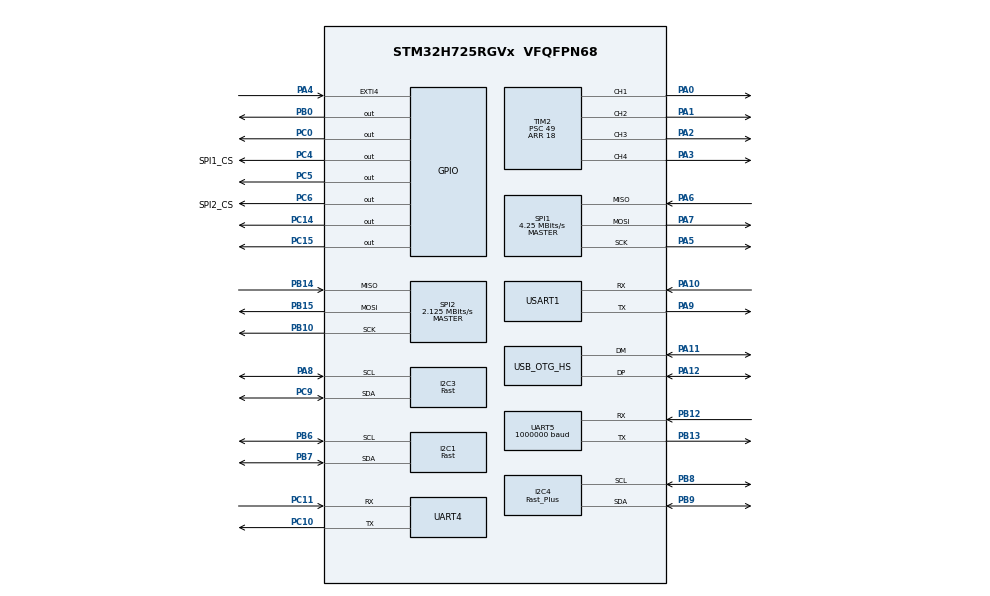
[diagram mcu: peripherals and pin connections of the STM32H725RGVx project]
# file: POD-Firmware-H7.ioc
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Bdma.I2C4_RX.0.Direction=DMA_PERIPH_TO_MEMORY
Bdma.I2C4_RX.0.EventEnable=DISABLE
Bdma.I2C4_RX.0.Instance=BDMA_Channel0
Bdma.I2C4_RX.0.MemDataAlignment=DMA_MDATAALIGN_BYTE
Bdma.I2C4_RX.0.MemInc=DMA_MINC_ENABLE
Bdma.I2C4_RX.0.Mode=DMA_NORMAL
Bdma.I2C4_RX.0.PeriphDataAlignment=DMA_PDATAALIGN_BYTE
Bdma.I2C4_RX.0.PeriphInc=DMA_PINC_DISABLE
Bdma.I2C4_RX.0.Polarity=HAL_DMAMUX_REQ_GEN_RISING
Bdma.I2C4_RX.0.Priority=DMA_PRIORITY_MEDIUM
Bdma.I2C4_RX.0.RequestNumber=1
Bdma.I2C4_RX.0.SignalID=NONE
Bdma.I2C4_RX.0.SyncEnable=DISABLE
Bdma.I2C4_RX.0.SyncPolarity=HAL_DMAMUX_SYNC_NO_EVENT
Bdma.I2C4_RX.0.SyncRequestNumber=1
Bdma.I2C4_RX.0.SyncSignalID=NONE
Bdma.Request0=I2C4_RX
Bdma.RequestsNb=1
CORTEX_M7.Enable_Spec=__NULL
Dma.I2C1_RX.0.Direction=DMA_PERIPH_TO_MEMORY
Dma.I2C1_RX.0.EventEnable=DISABLE
Dma.I2C1_RX.0.FIFOMode=DMA_FIFOMODE_DISABLE
Dma.I2C1_RX.0.Instance=DMA1_Stream0
Dma.I2C1_RX.0.MemDataAlignment=DMA_MDATAALIGN_BYTE
Dma.I2C1_RX.0.MemInc=DMA_MINC_ENABLE
Dma.I2C1_RX.0.Mode=DMA_NORMAL
Dma.I2C1_RX.0.PeriphDataAlignment=DMA_PDATAALIGN_BYTE
Dma.I2C1_RX.0.PeriphInc=DMA_PINC_DISABLE
Dma.I2C1_RX.0.Polarity=HAL_DMAMUX_REQ_GEN_RISING
Dma.I2C1_RX.0.Priority=DMA_PRIORITY_LOW
Dma.I2C1_RX.0.RequestNumber=1
Dma.I2C1_RX.0.SignalID=NONE
Dma.I2C1_RX.0.SyncEnable=DISABLE
Dma.I2C1_RX.0.SyncPolarity=HAL_DMAMUX_SYNC_NO_EVENT
Dma.I2C1_RX.0.SyncRequestNumber=1
Dma.I2C1_RX.0.SyncSignalID=NONE
Dma.I2C3_RX.1.Direction=DMA_PERIPH_TO_MEMORY
Dma.I2C3_RX.1.EventEnable=DISABLE
Dma.I2C3_RX.1.FIFOMode=DMA_FIFOMODE_DISABLE
Dma.I2C3_RX.1.Instance=DMA1_Stream1
Dma.I2C3_RX.1.MemDataAlignment=DMA_MDATAALIGN_BYTE
Dma.I2C3_RX.1.MemInc=DMA_MINC_ENABLE
Dma.I2C3_RX.1.Mode=DMA_NORMAL
Dma.I2C3_RX.1.PeriphDataAlignment=DMA_PDATAALIGN_BYTE
Dma.I2C3_RX.1.PeriphInc=DMA_PINC_DISABLE
Dma.I2C3_RX.1.Polarity=HAL_DMAMUX_REQ_GEN_RISING
Dma.I2C3_RX.1.Priority=DMA_PRIORITY_HIGH
Dma.I2C3_RX.1.RequestNumber=1
Dma.I2C3_RX.1.SignalID=NONE
Dma.I2C3_RX.1.SyncEnable=DISABLE
Dma.I2C3_RX.1.SyncPolarity=HAL_DMAMUX_SYNC_NO_EVENT
Dma.I2C3_RX.1.SyncRequestNumber=1
Dma.I2C3_RX.1.SyncSignalID=NONE
Dma.Request0=I2C1_RX
Dma.Request1=I2C3_RX
Dma.Request10=SPI2_TX
Dma.Request11=UART4_TX
Dma.Request12=UART4_RX
Dma.Request13=UART5_RX
Dma.Request2=SPI1_RX
Dma.Request3=UART5_TX
Dma.Request4=TIM2_CH1
Dma.Request5=TIM2_CH3
Dma.Request6=TIM2_CH4
Dma.Request7=TIM2_CH2
Dma.Request8=SPI2_RX
Dma.Request9=SPI1_TX
Dma.SPI1_RX.2.Direction=DMA_PERIPH_TO_MEMORY
Dma.SPI1_RX.2.EventEnable=DISABLE
Dma.SPI1_RX.2.FIFOMode=DMA_FIFOMODE_DISABLE
Dma.SPI1_RX.2.Instance=DMA1_Stream2
Dma.SPI1_RX.2.MemDataAlignment=DMA_MDATAALIGN_BYTE
Dma.SPI1_RX.2.MemInc=DMA_MINC_ENABLE
Dma.SPI1_RX.2.Mode=DMA_NORMAL
Dma.SPI1_RX.2.PeriphDataAlignment=DMA_PDATAALIGN_BYTE
Dma.SPI1_RX.2.PeriphInc=DMA_PINC_DISABLE
Dma.SPI1_RX.2.Polarity=HAL_DMAMUX_REQ_GEN_RISING
Dma.SPI1_RX.2.Priority=DMA_PRIORITY_HIGH
Dma.SPI1_RX.2.RequestNumber=1
Dma.SPI1_RX.2.SignalID=NONE
Dma.SPI1_RX.2.SyncEnable=DISABLE
Dma.SPI1_RX.2.SyncPolarity=HAL_DMAMUX_SYNC_NO_EVENT
Dma.SPI1_RX.2.SyncRequestNumber=1
Dma.SPI1_RX.2.SyncSignalID=NONE
Dma.SPI1_TX.9.Direction=DMA_MEMORY_TO_PERIPH
Dma.SPI1_TX.9.EventEnable=DISABLE
Dma.SPI1_TX.9.FIFOMode=DMA_FIFOMODE_DISABLE
Dma.SPI1_TX.9.Instance=DMA2_Stream1
Dma.SPI1_TX.9.MemDataAlignment=DMA_MDATAALIGN_BYTE
Dma.SPI1_TX.9.MemInc=DMA_MINC_ENABLE
Dma.SPI1_TX.9.Mode=DMA_NORMAL
Dma.SPI1_TX.9.PeriphDataAlignment=DMA_PDATAALIGN_BYTE
Dma.SPI1_TX.9.PeriphInc=DMA_PINC_DISABLE
Dma.SPI1_TX.9.Polarity=HAL_DMAMUX_REQ_GEN_RISING
Dma.SPI1_TX.9.Priority=DMA_PRIORITY_HIGH
Dma.SPI1_TX.9.RequestNumber=1
Dma.SPI1_TX.9.SignalID=NONE
Dma.SPI1_TX.9.SyncEnable=DISABLE
Dma.SPI1_TX.9.SyncPolarity=HAL_DMAMUX_SYNC_NO_EVENT
Dma.SPI1_TX.9.SyncRequestNumber=1
Dma.SPI1_TX.9.SyncSignalID=NONE
Dma.SPI2_RX.8.Direction=DMA_PERIPH_TO_MEMORY
Dma.SPI2_RX.8.EventEnable=DISABLE
Dma.SPI2_RX.8.FIFOMode=DMA_FIFOMODE_DISABLE
Dma.SPI2_RX.8.Instance=DMA1_Stream3
Dma.SPI2_RX.8.MemDataAlignment=DMA_MDATAALIGN_BYTE
Dma.SPI2_RX.8.MemInc=DMA_MINC_ENABLE
Dma.SPI2_RX.8.Mode=DMA_NORMAL
Dma.SPI2_RX.8.PeriphDataAlignment=DMA_PDATAALIGN_BYTE
Dma.SPI2_RX.8.PeriphInc=DMA_PINC_DISABLE
Dma.SPI2_RX.8.Polarity=HAL_DMAMUX_REQ_GEN_RISING
Dma.SPI2_RX.8.Priority=DMA_PRIORITY_HIGH
Dma.SPI2_RX.8.RequestNumber=1
Dma.SPI2_RX.8.SignalID=NONE
Dma.SPI2_RX.8.SyncEnable=DISABLE
Dma.SPI2_RX.8.SyncPolarity=HAL_DMAMUX_SYNC_NO_EVENT
Dma.SPI2_RX.8.SyncRequestNumber=1
Dma.SPI2_RX.8.SyncSignalID=NONE
Dma.SPI2_TX.10.Direction=DMA_MEMORY_TO_PERIPH
Dma.SPI2_TX.10.EventEnable=DISABLE
Dma.SPI2_TX.10.FIFOMode=DMA_FIFOMODE_DISABLE
Dma.SPI2_TX.10.Instance=DMA2_Stream2
Dma.SPI2_TX.10.MemDataAlignment=DMA_MDATAALIGN_BYTE
Dma.SPI2_TX.10.MemInc=DMA_MINC_ENABLE
Dma.SPI2_TX.10.Mode=DMA_NORMAL
Dma.SPI2_TX.10.PeriphDataAlignment=DMA_PDATAALIGN_BYTE
Dma.SPI2_TX.10.PeriphInc=DMA_PINC_DISABLE
Dma.SPI2_TX.10.Polarity=HAL_DMAMUX_REQ_GEN_RISING
Dma.SPI2_TX.10.Priority=DMA_PRIORITY_HIGH
Dma.SPI2_TX.10.RequestNumber=1
Dma.SPI2_TX.10.SignalID=NONE
Dma.SPI2_TX.10.SyncEnable=DISABLE
Dma.SPI2_TX.10.SyncPolarity=HAL_DMAMUX_SYNC_NO_EVENT
Dma.SPI2_TX.10.SyncRequestNumber=1
Dma.SPI2_TX.10.SyncSignalID=NONE
Dma.TIM2_CH1.4.Direction=DMA_MEMORY_TO_PERIPH
Dma.TIM2_CH1.4.EventEnable=DISABLE
Dma.TIM2_CH1.4.FIFOMode=DMA_FIFOMODE_DISABLE
Dma.TIM2_CH1.4.Instance=DMA1_Stream4
Dma.TIM2_CH1.4.MemDataAlignment=DMA_MDATAALIGN_WORD
Dma.TIM2_CH1.4.MemInc=DMA_MINC_ENABLE
Dma.TIM2_CH1.4.Mode=DMA_NORMAL
Dma.TIM2_CH1.4.PeriphDataAlignment=DMA_PDATAALIGN_WORD
Dma.TIM2_CH1.4.PeriphInc=DMA_PINC_DISABLE
Dma.TIM2_CH1.4.Polarity=HAL_DMAMUX_REQ_GEN_RISING
Dma.TIM2_CH1.4.Priority=DMA_PRIORITY_VERY_HIGH
Dma.TIM2_CH1.4.RequestNumber=1
Dma.TIM2_CH1.4.SignalID=NONE
Dma.TIM2_CH1.4.SyncEnable=DISABLE
Dma.TIM2_CH1.4.SyncPolarity=HAL_DMAMUX_SYNC_NO_EVENT
Dma.TIM2_CH1.4.SyncRequestNumber=1
Dma.TIM2_CH1.4.SyncSignalID=NONE
Dma.TIM2_CH2.7.Direction=DMA_MEMORY_TO_PERIPH
Dma.TIM2_CH2.7.EventEnable=DISABLE
Dma.TIM2_CH2.7.FIFOMode=DMA_FIFOMODE_DISABLE
Dma.TIM2_CH2.7.Instance=DMA1_Stream5
Dma.TIM2_CH2.7.MemDataAlignment=DMA_MDATAALIGN_WORD
Dma.TIM2_CH2.7.MemInc=DMA_MINC_ENABLE
Dma.TIM2_CH2.7.Mode=DMA_NORMAL
Dma.TIM2_CH2.7.PeriphDataAlignment=DMA_PDATAALIGN_WORD
Dma.TIM2_CH2.7.PeriphInc=DMA_PINC_DISABLE
Dma.TIM2_CH2.7.Polarity=HAL_DMAMUX_REQ_GEN_RISING
Dma.TIM2_CH2.7.Priority=DMA_PRIORITY_VERY_HIGH
Dma.TIM2_CH2.7.RequestNumber=1
Dma.TIM2_CH2.7.SignalID=NONE
Dma.TIM2_CH2.7.SyncEnable=DISABLE
Dma.TIM2_CH2.7.SyncPolarity=HAL_DMAMUX_SYNC_NO_EVENT
Dma.TIM2_CH2.7.SyncRequestNumber=1
Dma.TIM2_CH2.7.SyncSignalID=NONE
Dma.TIM2_CH3.5.Direction=DMA_MEMORY_TO_PERIPH
Dma.TIM2_CH3.5.EventEnable=DISABLE
Dma.TIM2_CH3.5.FIFOMode=DMA_FIFOMODE_DISABLE
Dma.TIM2_CH3.5.Instance=DMA1_Stream6
Dma.TIM2_CH3.5.MemDataAlignment=DMA_MDATAALIGN_WORD
Dma.TIM2_CH3.5.MemInc=DMA_MINC_ENABLE
Dma.TIM2_CH3.5.Mode=DMA_NORMAL
Dma.TIM2_CH3.5.PeriphDataAlignment=DMA_PDATAALIGN_WORD
Dma.TIM2_CH3.5.PeriphInc=DMA_PINC_DISABLE
Dma.TIM2_CH3.5.Polarity=HAL_DMAMUX_REQ_GEN_RISING
Dma.TIM2_CH3.5.Priority=DMA_PRIORITY_VERY_HIGH
Dma.TIM2_CH3.5.RequestNumber=1
Dma.TIM2_CH3.5.SignalID=NONE
Dma.TIM2_CH3.5.SyncEnable=DISABLE
Dma.TIM2_CH3.5.SyncPolarity=HAL_DMAMUX_SYNC_NO_EVENT
Dma.TIM2_CH3.5.SyncRequestNumber=1
Dma.TIM2_CH3.5.SyncSignalID=NONE
Dma.TIM2_CH4.6.Direction=DMA_MEMORY_TO_PERIPH
Dma.TIM2_CH4.6.EventEnable=DISABLE
Dma.TIM2_CH4.6.FIFOMode=DMA_FIFOMODE_DISABLE
Dma.TIM2_CH4.6.Instance=DMA1_Stream7
Dma.TIM2_CH4.6.MemDataAlignment=DMA_MDATAALIGN_WORD
Dma.TIM2_CH4.6.MemInc=DMA_MINC_ENABLE
Dma.TIM2_CH4.6.Mode=DMA_NORMAL
Dma.TIM2_CH4.6.PeriphDataAlignment=DMA_PDATAALIGN_WORD
Dma.TIM2_CH4.6.PeriphInc=DMA_PINC_DISABLE
Dma.TIM2_CH4.6.Polarity=HAL_DMAMUX_REQ_GEN_RISING
Dma.TIM2_CH4.6.Priority=DMA_PRIORITY_VERY_HIGH
Dma.TIM2_CH4.6.RequestNumber=1
Dma.TIM2_CH4.6.SignalID=NONE
Dma.TIM2_CH4.6.SyncEnable=DISABLE
Dma.TIM2_CH4.6.SyncPolarity=HAL_DMAMUX_SYNC_NO_EVENT
Dma.TIM2_CH4.6.SyncRequestNumber=1
Dma.TIM2_CH4.6.SyncSignalID=NONE
Dma.UART4_RX.12.Direction=DMA_PERIPH_TO_MEMORY
Dma.UART4_RX.12.EventEnable=DISABLE
Dma.UART4_RX.12.FIFOMode=DMA_FIFOMODE_DISABLE
Dma.UART4_RX.12.Instance=DMA2_Stream4
Dma.UART4_RX.12.MemDataAlignment=DMA_MDATAALIGN_BYTE
Dma.UART4_RX.12.MemInc=DMA_MINC_ENABLE
Dma.UART4_RX.12.Mode=DMA_NORMAL
Dma.UART4_RX.12.PeriphDataAlignment=DMA_PDATAALIGN_BYTE
Dma.UART4_RX.12.PeriphInc=DMA_PINC_DISABLE
Dma.UART4_RX.12.Polarity=HAL_DMAMUX_REQ_GEN_RISING
Dma.UART4_RX.12.Priority=DMA_PRIORITY_MEDIUM
Dma.UART4_RX.12.RequestNumber=1
Dma.UART4_RX.12.SignalID=NONE
Dma.UART4_RX.12.SyncEnable=DISABLE
Dma.UART4_RX.12.SyncPolarity=HAL_DMAMUX_SYNC_NO_EVENT
Dma.UART4_RX.12.SyncRequestNumber=1
Dma.UART4_RX.12.SyncSignalID=NONE
Dma.UART4_TX.11.Direction=DMA_MEMORY_TO_PERIPH
Dma.UART4_TX.11.EventEnable=DISABLE
Dma.UART4_TX.11.FIFOMode=DMA_FIFOMODE_DISABLE
Dma.UART4_TX.11.Instance=DMA2_Stream3
Dma.UART4_TX.11.MemDataAlignment=DMA_MDATAALIGN_BYTE
Dma.UART4_TX.11.MemInc=DMA_MINC_ENABLE
Dma.UART4_TX.11.Mode=DMA_NORMAL
Dma.UART4_TX.11.PeriphDataAlignment=DMA_PDATAALIGN_BYTE
Dma.UART4_TX.11.PeriphInc=DMA_PINC_DISABLE
Dma.UART4_TX.11.Polarity=HAL_DMAMUX_REQ_GEN_RISING
Dma.UART4_TX.11.Priority=DMA_PRIORITY_MEDIUM
Dma.UART4_TX.11.RequestNumber=1
Dma.UART4_TX.11.SignalID=NONE
Dma.UART4_TX.11.SyncEnable=DISABLE
Dma.UART4_TX.11.SyncPolarity=HAL_DMAMUX_SYNC_NO_EVENT
Dma.UART4_TX.11.SyncRequestNumber=1
Dma.UART4_TX.11.SyncSignalID=NONE
Dma.UART5_RX.13.Direction=DMA_PERIPH_TO_MEMORY
Dma.UART5_RX.13.EventEnable=DISABLE
Dma.UART5_RX.13.FIFOMode=DMA_FIFOMODE_DISABLE
Dma.UART5_RX.13.Instance=DMA2_Stream5
Dma.UART5_RX.13.MemDataAlignment=DMA_MDATAALIGN_BYTE
Dma.UART5_RX.13.MemInc=DMA_MINC_ENABLE
Dma.UART5_RX.13.Mode=DMA_CIRCULAR
Dma.UART5_RX.13.PeriphDataAlignment=DMA_PDATAALIGN_BYTE
Dma.UART5_RX.13.PeriphInc=DMA_PINC_DISABLE
Dma.UART5_RX.13.Polarity=HAL_DMAMUX_REQ_GEN_RISING
Dma.UART5_RX.13.Priority=DMA_PRIORITY_VERY_HIGH
Dma.UART5_RX.13.RequestNumber=1
Dma.UART5_RX.13.SignalID=NONE
Dma.UART5_RX.13.SyncEnable=DISABLE
Dma.UART5_RX.13.SyncPolarity=HAL_DMAMUX_SYNC_NO_EVENT
Dma.UART5_RX.13.SyncRequestNumber=1
Dma.UART5_RX.13.SyncSignalID=NONE
Dma.UART5_TX.3.Direction=DMA_MEMORY_TO_PERIPH
Dma.UART5_TX.3.EventEnable=DISABLE
Dma.UART5_TX.3.FIFOMode=DMA_FIFOMODE_DISABLE
Dma.UART5_TX.3.Instance=DMA2_Stream0
Dma.UART5_TX.3.MemDataAlignment=DMA_MDATAALIGN_BYTE
Dma.UART5_TX.3.MemInc=DMA_MINC_ENABLE
Dma.UART5_TX.3.Mode=DMA_NORMAL
Dma.UART5_TX.3.PeriphDataAlignment=DMA_PDATAALIGN_BYTE
Dma.UART5_TX.3.PeriphInc=DMA_PINC_DISABLE
Dma.UART5_TX.3.Polarity=HAL_DMAMUX_REQ_GEN_RISING
Dma.UART5_TX.3.Priority=DMA_PRIORITY_MEDIUM
Dma.UART5_TX.3.RequestNumber=1
Dma.UART5_TX.3.SignalID=NONE
Dma.UART5_TX.3.SyncEnable=DISABLE
Dma.UART5_TX.3.SyncPolarity=HAL_DMAMUX_SYNC_NO_EVENT
Dma.UART5_TX.3.SyncRequestNumber=1
Dma.UART5_TX.3.SyncSignalID=NONE
FREERTOS.Tasks01=defaultTask,24,128,StartDefaultTask,Default,NULL,Dynamic,NULL,NULL
FREERTOS.configENABLE_FPU=1
I2C1.I2C_Speed_Mode=I2C_Fast
I2C1.Timing=0x00D049F7
I2C3.I2C_Speed_Mode=I2C_Fast
I2C3.Timing=0x00D049F7
I2C4.I2C_Speed_Mode=I2C_Fast_Plus
I2C4.Timing=0x00601B59
Mcu.Family=STM32H7
Mcu.Name=STM32H725RGVx
Mcu.Package=VFQFPN68
NVIC.BDMA_Channel0_IRQn=true\:6\:0\:true\:false\:true\:true\:false\:true\:true
NVIC.DMA1_Stream0_IRQn=true\:6\:0\:true\:false\:true\:true\:false\:true\:true
NVIC.DMA1_Stream1_IRQn=true\:6\:0\:true\:false\:true\:true\:false\:true\:true
NVIC.DMA1_Stream2_IRQn=true\:7\:0\:true\:false\:true\:true\:false\:true\:true
NVIC.DMA1_Stream3_IRQn=true\:6\:0\:true\:false\:true\:true\:false\:true\:true
NVIC.DMA1_Stream4_IRQn=true\:6\:0\:true\:false\:true\:true\:false\:true\:true
NVIC.DMA1_Stream5_IRQn=true\:6\:0\:true\:false\:true\:true\:false\:true\:true
NVIC.DMA1_Stream6_IRQn=true\:6\:0\:true\:false\:true\:true\:false\:true\:true
NVIC.DMA1_Stream7_IRQn=true\:6\:0\:true\:false\:true\:true\:false\:true\:true
NVIC.DMA2_Stream0_IRQn=true\:6\:0\:true\:false\:true\:true\:false\:true\:true
NVIC.DMA2_Stream1_IRQn=true\:7\:0\:true\:false\:true\:true\:false\:true\:true
NVIC.DMA2_Stream2_IRQn=true\:6\:0\:true\:false\:true\:true\:false\:true\:true
NVIC.DMA2_Stream3_IRQn=true\:6\:0\:true\:false\:true\:true\:false\:true\:true
NVIC.DMA2_Stream4_IRQn=true\:6\:0\:true\:false\:true\:true\:false\:true\:true
NVIC.DMA2_Stream5_IRQn=true\:5\:0\:false\:false\:true\:true\:false\:true\:true
NVIC.I2C1_EV_IRQn=true\:6\:0\:true\:false\:true\:true\:true\:true\:true
NVIC.I2C3_EV_IRQn=true\:6\:0\:true\:false\:true\:true\:true\:true\:true
NVIC.I2C4_EV_IRQn=true\:7\:0\:true\:false\:true\:true\:true\:true\:true
NVIC.OTG_HS_IRQn=true\:6\:0\:true\:false\:true\:true\:false\:true\:true
NVIC.PriorityGroup=NVIC_PRIORITYGROUP_4
NVIC.SPI1_IRQn=true\:6\:0\:true\:false\:true\:true\:true\:true\:true
NVIC.SPI2_IRQn=true\:6\:0\:true\:false\:true\:true\:true\:true\:true
NVIC.TIM1_UP_IRQn=true\:15\:0\:false\:false\:true\:false\:false\:true\:true
NVIC.TIM6_DAC_IRQn=true\:6\:0\:true\:false\:true\:true\:true\:true\:true
NVIC.TimeBase=TIM1_UP_IRQn
NVIC.TimeBaseIP=TIM1
NVIC.UART4_IRQn=true\:6\:0\:true\:false\:true\:true\:true\:true\:true
NVIC.UART5_IRQn=true\:6\:0\:true\:false\:true\:true\:true\:true\:true
PA0.Signal=S_TIM2_CH1_ETR
PA1.Signal=S_TIM2_CH2
PA10.Mode=Asynchronous
PA10.Signal=USART1_RX
PA11.Mode=Device_Only_FS
PA11.Signal=USB_OTG_HS_DM
PA12.Mode=Device_Only_FS
PA12.Signal=USB_OTG_HS_DP
PA13(JTMS/SWDIO).Signal=DEBUG_JTMS-SWDIO
PA14(JTCK/SWCLK).Signal=DEBUG_JTCK-SWCLK
PA2.Signal=S_TIM2_CH3
PA3.Signal=S_TIM2_CH4
PA4.Signal=GPXTI4
PA5.Mode=Full_Duplex_Master
PA5.Signal=SPI1_SCK
PA6.Mode=Full_Duplex_Master
PA6.Signal=SPI1_MISO
PA7.Mode=Full_Duplex_Master
PA7.Signal=SPI1_MOSI
PA8.Mode=I2C
PA8.Signal=I2C3_SCL
PA9.Mode=Asynchronous
PA9.Signal=USART1_TX
PB0.Signal=GPIO_Output
PB10.Mode=Full_Duplex_Master
PB10.Signal=SPI2_SCK
PB12.Mode=Asynchronous
PB12.Signal=UART5_RX
PB13.Mode=Asynchronous
PB13.Signal=UART5_TX
PB14.Mode=Full_Duplex_Master
PB14.Signal=SPI2_MISO
PB15.Mode=Full_Duplex_Master
PB15.Signal=SPI2_MOSI
PB3(JTDO/TRACESWO).Signal=DEBUG_JTDO-SWO
PB6.Mode=I2C
PB6.Signal=I2C1_SCL
PB7.Mode=I2C
PB7.Signal=I2C1_SDA
PB8.Mode=I2C
PB8.Signal=I2C4_SCL
PB9.Mode=I2C
PB9.Signal=I2C4_SDA
PC0.Signal=GPIO_Output
PC10.Mode=Asynchronous
PC10.Signal=UART4_TX
PC11.Mode=Asynchronous
PC11.Signal=UART4_RX
PC14-OSC32_IN.Signal=GPIO_Output
PC15-OSC32_OUT.Signal=GPIO_Output
PC4.GPIO_Label=SPI1_CS
PC4.Signal=GPIO_Output
PC5.Signal=GPIO_Output
PC6.GPIO_Label=SPI2_CS
PC6.Signal=GPIO_Output
PC9.Mode=I2C
PC9.Signal=I2C3_SDA
PH0-OSC_IN.Mode=HSE-External-Oscillator
PH0-OSC_IN.Signal=RCC_OSC_IN
PH1-OSC_OUT.Mode=HSE-External-Oscillator
PH1-OSC_OUT.Signal=RCC_OSC_OUT
ProjectManager.HeapSize=0x200
ProjectManager.StackSize=0x400
ProjectManager.TargetToolchain=Makefile
RCC.ADCFreq_Value=16125000
RCC.APB1Freq_Value=136000000
RCC.APB2Freq_Value=136000000
RCC.APB3Freq_Value=136000000
RCC.APB4Freq_Value=136000000
RCC.CortexFreq_Value=544000000
RCC.D1PPRE=RCC_APB3_DIV2
RCC.D2PPRE1=RCC_APB1_DIV2
RCC.D2PPRE2=RCC_APB2_DIV2
RCC.D3PPRE=RCC_APB4_DIV2
RCC.DIVM1=1
RCC.DIVM3=1
RCC.DIVN1=68
RCC.DIVN3=24
RCC.DIVP1=1
RCC.DIVQ1=4
RCC.DIVQ3=4
RCC.DIVR3=4
RCC.HCLKFreq_Value=272000000
RCC.HPRE=RCC_HCLK_DIV2
RCC.HSE_VALUE=8000000
RCC.PLL2FRACN=0
RCC.PLL3FRACN=0
RCC.PLLFRACN=0
RCC.PLLSourceVirtual=RCC_PLLSOURCE_HSE
RCC.SYSCLKFreq_VALUE=544000000
RCC.SYSCLKSource=RCC_SYSCLKSOURCE_PLLCLK
RCC.USBCLockSelection=RCC_USBCLKSOURCE_PLL3
RCC.USBFreq_Value=48000000
SH.S_TIM2_CH1_ETR.0=TIM2_CH1,PWM Generation1 CH1
SH.S_TIM2_CH2.0=TIM2_CH2,PWM Generation2 CH2
SH.S_TIM2_CH3.0=TIM2_CH3,PWM Generation3 CH3
SH.S_TIM2_CH4.0=TIM2_CH4,PWM Generation4 CH4
SPI1.BaudRatePrescaler=SPI_BAUDRATEPRESCALER_32
SPI1.CalculateBaudRate=4.25 MBits/s
SPI1.DataSize=SPI_DATASIZE_8BIT
SPI1.Direction=SPI_DIRECTION_2LINES
SPI1.Mode=SPI_MODE_MASTER
SPI1.VirtualType=VM_MASTER
SPI2.BaudRatePrescaler=SPI_BAUDRATEPRESCALER_64
SPI2.CalculateBaudRate=2.125 MBits/s
SPI2.DataSize=SPI_DATASIZE_8BIT
SPI2.Direction=SPI_DIRECTION_2LINES
SPI2.Mode=SPI_MODE_MASTER
SPI2.VirtualType=VM_MASTER
TIM2.AutoReloadPreload=TIM_AUTORELOAD_PRELOAD_ENABLE
TIM2.Channel-PWM\ Generation1\ CH1=TIM_CHANNEL_1
TIM2.Channel-PWM\ Generation2\ CH2=TIM_CHANNEL_2
TIM2.Channel-PWM\ Generation3\ CH3=TIM_CHANNEL_3
TIM2.Channel-PWM\ Generation4\ CH4=TIM_CHANNEL_4
TIM2.Period=18
TIM2.Prescaler=49
TIM6.AutoReloadPreload=TIM_AUTORELOAD_PRELOAD_ENABLE
TIM6.Period=499
TIM6.Prescaler=271
TIM6.TIM_MasterOutputTrigger=TIM_TRGO_UPDATE
TIM7.AutoReloadPreload=TIM_AUTORELOAD_PRELOAD_ENABLE
TIM7.Prescaler=271
UART5.BaudRate=1000000
USART1.VirtualMode-Asynchronous=VM_ASYNC
USB_DEVICE.CLASS_NAME_HS=CDC
USB_DEVICE.VirtualMode=Cdc
USB_DEVICE.VirtualModeHS=Cdc_HS
USB_OTG_HS.VirtualMode=Device_Only_FS
VP_FREERTOS_VS_CMSIS_V2.Mode=CMSIS_V2
VP_SYS_VS_tim1.Mode=TIM1
VP_TIM6_VS_ClockSourceINT.Mode=Enable_Timer
VP_TIM7_VS_ClockSourceINT.Mode=Enable_Timer
VP_USB_DEVICE_VS_USB_DEVICE_CDC_HS.Mode=CDC_HS
board=custom

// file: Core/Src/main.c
/* USER CODE BEGIN Header */
/**
  ******************************************************************************
  * @file           : main.c
  * @brief          : Main program body
  ******************************************************************************
  * @attention
  *
  * Copyright (c) 2024 STMicroelectronics.
  * All rights reserved.
  *
  * This software is licensed under terms that can be found in the LICENSE file
  * in the root directory of this software component.
  * If no LICENSE file comes with this software, it is provided AS-IS.
  *
  ******************************************************************************
  */
/* USER CODE END Header */
#include "main.h"
#include "cmsis_os.h"
#include "bdma.h"
#include "dma.h"
#include "i2c.h"
#include "spi.h"
#include "tim.h"
#include "usart.h"
#include "usb_device.h"
#include "gpio.h"

/* USER CODE BEGIN Includes */
#include "debug.h"
#include "motor_power.h"
#include "_config.h"
/* USER CODE END Includes */

void SystemClock_Config(void);
void MX_FREERTOS_Init(void);

int main(void)
{

  /* MCU Configuration--------------------------------------------------------*/

  /* Reset of all peripherals, Initializes the Flash interface and the Systick. */
  HAL_Init();

  /* Configure the system clock */
  SystemClock_Config();

  /* USER CODE BEGIN SysInit */
  MX_DMA_Init();
  MX_BDMA_Init();
  /* USER CODE END SysInit */

  /* Initialize all configured peripherals */
  MX_GPIO_Init();
  MX_I2C1_Init();
  MX_I2C3_Init();
  MX_I2C4_Init();
  MX_SPI1_Init();
  MX_SPI2_Init();
  MX_DMA_Init();
  MX_UART5_Init();
  MX_UART4_Init();
  MX_BDMA_Init();
  MX_TIM6_Init();
  MX_TIM2_Init();
  MX_TIM7_Init();
  MX_USART1_UART_Init();
  /* USER CODE BEGIN 2 */
  DEBUG_PRINT("Firmware start\n");
  /* USER CODE END 2 */

  /* Init scheduler */
  osKernelInitialize();  /* Call init function for freertos objects (in freertos.c) */
  MX_FREERTOS_Init();

  /* Start scheduler */
  osKernelStart();

  /* We should never get here as control is now taken by the scheduler */
  /* Infinite loop */
  while (1)
  {

  }
}

void SystemClock_Config(void)
{
  RCC_OscInitTypeDef RCC_OscInitStruct = {0};
  RCC_ClkInitTypeDef RCC_ClkInitStruct = {0};

  /** Supply configuration update enable
  */
  HAL_PWREx_ConfigSupply(PWR_DIRECT_SMPS_SUPPLY);

  /** Configure the main internal regulator output voltage
  */
  __HAL_PWR_VOLTAGESCALING_CONFIG(PWR_REGULATOR_VOLTAGE_SCALE0);

  while(!__HAL_PWR_GET_FLAG(PWR_FLAG_VOSRDY)) {}

  /** Macro to configure the PLL clock source
  */
  __HAL_RCC_PLL_PLLSOURCE_CONFIG(RCC_PLLSOURCE_HSE);

  /** Initializes the RCC Oscillators according to the specified parameters
  * in the RCC_OscInitTypeDef structure.
  */
  RCC_OscInitStruct.OscillatorType = RCC_OSCILLATORTYPE_HSE;
  RCC_OscInitStruct.HSEState = RCC_HSE_ON;
  RCC_OscInitStruct.PLL.PLLState = RCC_PLL_ON;
  RCC_OscInitStruct.PLL.PLLSource = RCC_PLLSOURCE_HSE;
  RCC_OscInitStruct.PLL.PLLM = 1;
  RCC_OscInitStruct.PLL.PLLN = 68;
  RCC_OscInitStruct.PLL.PLLP = 1;
  RCC_OscInitStruct.PLL.PLLQ = 4;
  RCC_OscInitStruct.PLL.PLLR = 2;
  RCC_OscInitStruct.PLL.PLLRGE = RCC_PLL1VCIRANGE_3;
  RCC_OscInitStruct.PLL.PLLVCOSEL = RCC_PLL1VCOWIDE;
  RCC_OscInitStruct.PLL.PLLFRACN = 0;
  if (HAL_RCC_OscConfig(&RCC_OscInitStruct) != HAL_OK)
  {
    Error_Handler();
  }

  /** Initializes the CPU, AHB and APB buses clocks
  */
  RCC_ClkInitStruct.ClockType = RCC_CLOCKTYPE_HCLK|RCC_CLOCKTYPE_SYSCLK
                              |RCC_CLOCKTYPE_PCLK1|RCC_CLOCKTYPE_PCLK2
                              |RCC_CLOCKTYPE_D3PCLK1|RCC_CLOCKTYPE_D1PCLK1;
  RCC_ClkInitStruct.SYSCLKSource = RCC_SYSCLKSOURCE_PLLCLK;
  RCC_ClkInitStruct.SYSCLKDivider = RCC_SYSCLK_DIV1;
  RCC_ClkInitStruct.AHBCLKDivider = RCC_HCLK_DIV2;
  RCC_ClkInitStruct.APB3CLKDivider = RCC_APB3_DIV2;
  RCC_ClkInitStruct.APB1CLKDivider = RCC_APB1_DIV2;
  RCC_ClkInitStruct.APB2CLKDivider = RCC_APB2_DIV2;
  RCC_ClkInitStruct.APB4CLKDivider = RCC_APB4_DIV2;

  if (HAL_RCC_ClockConfig(&RCC_ClkInitStruct, FLASH_LATENCY_3) != HAL_OK)
  {
    Error_Handler();
  }
}

void HAL_TIM_PeriodElapsedCallback(TIM_HandleTypeDef *htim)
{
  /* USER CODE BEGIN Callback 0 */
  if (htim->Instance == MOTOR_TIM.Instance) {
    motorPowerSend();
  }
  /* USER CODE END Callback 0 */
  if (htim->Instance == TIM1) {
    HAL_IncTick();
  }
}

void Error_Handler(void)
{
  __disable_irq();
  while (1)
  {
  }
}

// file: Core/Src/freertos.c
/* USER CODE BEGIN Header */
/**
  ******************************************************************************
  * File Name          : freertos.c
  * Description        : Code for freertos applications
  ******************************************************************************
  * @attention
  *
  * Copyright (c) 2024 STMicroelectronics.
  * All rights reserved.
  *
  * This software is licensed under terms that can be found in the LICENSE file
  * in the root directory of this software component.
  * If no LICENSE file comes with this software, it is provided AS-IS.
  *
  ******************************************************************************
  */
/* USER CODE END Header */

#include "FreeRTOS.h"
#include "task.h"
#include "main.h"
#include "cmsis_os.h"

/* USER CODE BEGIN Includes */
#include "system.h"
#include "led.h"
/* USER CODE END Includes */

/* Definitions for defaultTask */
osThreadId_t defaultTaskHandle;
const osThreadAttr_t defaultTask_attributes = {
  .name = "defaultTask",
  .stack_size = 128 * 4,
  .priority = (osPriority_t) osPriorityNormal,
};

void StartDefaultTask(void *argument);

extern void MX_USB_DEVICE_Init(void);
void MX_FREERTOS_Init(void); /* (MISRA C 2004 rule 8.1) */

void MX_FREERTOS_Init(void) {
  /* USER CODE BEGIN Init */
  systemInit();
  /* USER CODE END Init */

  /* Create the thread(s) */
  /* creation of defaultTask */
  defaultTaskHandle = osThreadNew(StartDefaultTask, NULL, &defaultTask_attributes);

}

void StartDefaultTask(void *argument)
{
  /* init code for USB_DEVICE */
  MX_USB_DEVICE_Init();
  /* USER CODE BEGIN StartDefaultTask */
  /* Infinite loop */
  for(;;)
  {
    osDelay(1000);
  }
  /* USER CODE END StartDefaultTask */
}
